# nrf9220_cellrf register map
Vendor: Nordic Semiconductor; Series: nRF92; File version: 1
CPU: CM0 r0p0, little endian, no MPU, no FPU, 2 interrupt priority bits, 33 interrupts
Registers are 32-bit, read-write, reset 0x0 unless marked. A register's access mark holds for its fields unless they carry their own. Offsets are from the block's base; [hi:lo] are bit positions; {n}, {i} and the like mark numbered series; 'fields as' and 'values as' point back to an identical list.

## GLOBAL_CTI210 — Cross-Trigger Interface control. NOTE: this is not a separate peripheral, but describes CM33 functionality. 0
Base 0xBF046000
Same registers: GLOBAL_CTI211 0xBF047000
0x00 CTICONTROL
  [0] GLBEN — Enables or disables the CTI.
    0=Disabled (All cross-triggering mapping logic functionality is disabled.); 1=Enabled (Cross-triggering mapping logic functionality is enabled.)
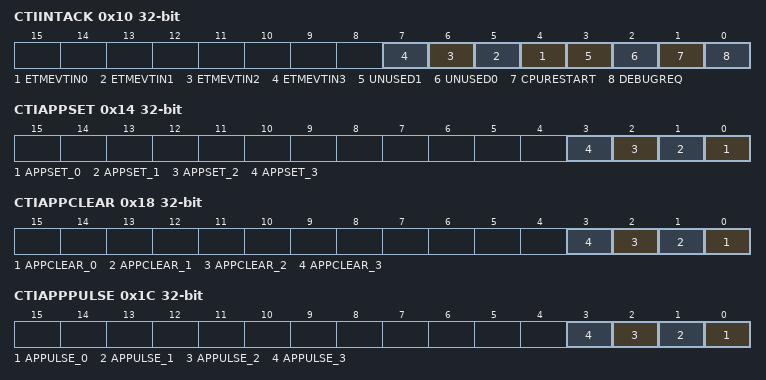
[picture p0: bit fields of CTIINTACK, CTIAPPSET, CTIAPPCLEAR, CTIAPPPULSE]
0x10 CTIINTACK wo — CTI Interrupt Acknowledge register
  [all] fields
    on write: 1=Acknowledge (Clears the ctitrigout.)
  [n+4] ETMEVTIN{n} (n=0..3) — ETM Event Input {n}
  [3] UNUSED1
  [2] UNUSED0
  [1] CPURESTART — Processor Restart
  [0] DEBUGREQ — Processor debug request
0x14 CTIAPPSET — CTI Application Trigger Set register
  [n] APPSET_{n} (n=0..3) — Application trigger event for channel {n}.
    on read: 0=Inactive (Application trigger {n} is inactive.); 1=Active (Application trigger {n} is active.) | on write: 1=Activate (Generate channel event for channel {n}.)
0x18 CTIAPPCLEAR wo — CTI Application Trigger Clear register
  [n] APPCLEAR_{n} (n=0..3) — Sets the corresponding bits in the CTIAPPSET to 0. There is one bit of the register for each channel.
    on write: 1=Clears the event for channel {n}
0x1C CTIAPPPULSE wo — CTI Application Pulse register
  [n] APPULSE_{n} (n=0..3) — Setting a bit HIGH generates a channel event pulse for the selected channel. There is one bit of the register for each channel.
    on write: 1=Generates an event pulse on channel {n}
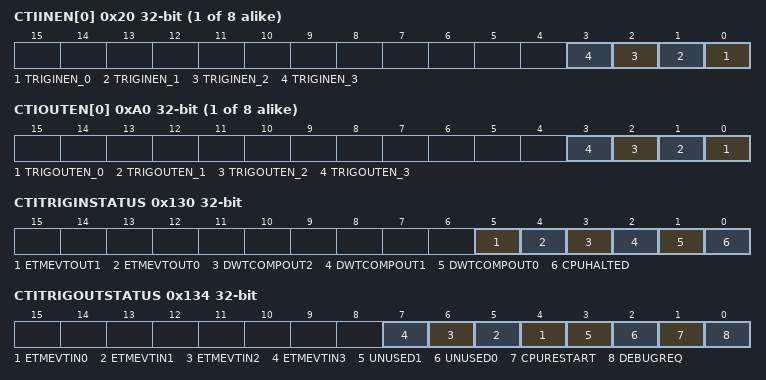
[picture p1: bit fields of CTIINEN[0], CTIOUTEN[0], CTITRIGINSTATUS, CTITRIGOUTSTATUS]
{0x20+4i} CTIINEN[{i}] (i=0..7) — Description collection: CTI Trigger input
  [n] TRIGINEN_{n} (n=0..3) — Enables a cross trigger event to channel {n} when a ctitrigin input is activated.
    0=Disabled (Input trigger n events are ignored by channel {n}.); 1=Enabled (When an event is received on input trigger n (ctitrigin[n]), generate an event on channel {n}.)
{0xA0+4i} CTIOUTEN[{i}] (i=0..7) — Description collection: CTI Trigger output
  [n] TRIGOUTEN_{n} (n=0..3) — Enables a cross trigger event to ctitrigout when channel {n} is activated.
    0=Disabled (Channel {n} is ignored by output trigger n.); 1=Enabled (When an event occurs on channel {n}, generate an event on output event n (ctitrigout[n]).)
0x130 CTITRIGINSTATUS ro — CTI Trigger In Status register Because the register provides a view of the raw ctitrigin inputs, the reset value is UNKNOWN.
  [all] fields
    1=Active (Ctitrigin is active.); 0=Inactive (Ctitrigin is inactive.)
  [5] ETMEVTOUT1 — ETM Event Output 1
  [4] ETMEVTOUT0 — ETM Event Output 0
  [3] DWTCOMPOUT2 — DWT Comparator Output 2
  [2] DWTCOMPOUT1 — DWT Comparator Output 1
  [1] DWTCOMPOUT0 — DWT Comparator Output 0
  [0] CPUHALTED — Processor Halted
0x134 CTITRIGOUTSTATUS ro — CTI Trigger Out Status register
  [all] fields
    1=Active (Ctitrigout is active.); 0=Inactive (Ctitrigout is inactive.)
  [n+4] ETMEVTIN{n} (n=0..3) — ETM Event Input {n}
  [3] UNUSED1
  [2] UNUSED0
  [1] CPURESTART — Processor Restart
  [0] DEBUGREQ — Processor debug request
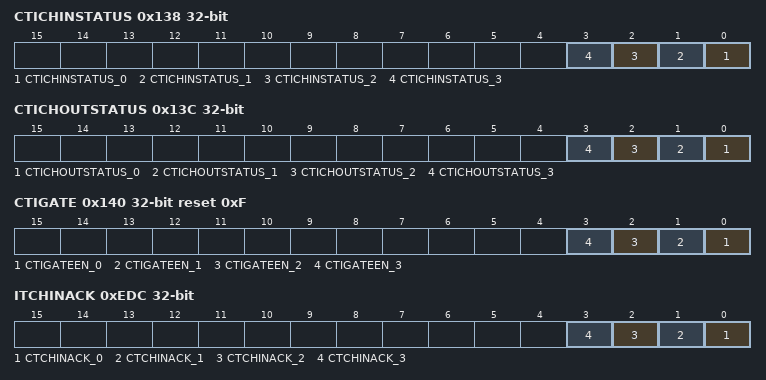
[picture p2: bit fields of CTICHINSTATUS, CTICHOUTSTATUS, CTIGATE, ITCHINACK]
0x138 CTICHINSTATUS ro — CTI Channel In Status register Because the register provides a view of the raw ctichin inputs, the reset value is UNKNOWN.
  [n] CTICHINSTATUS_{n} (n=0..3) — Shows the status of the ctitrigin {n} input.
    1=Active (Ctichin {n} is active.); 0=Inactive (Ctichin {n} is inactive.)
0x13C CTICHOUTSTATUS ro — CTI Channel Out Status register
  [n] CTICHOUTSTATUS_{n} (n=0..3) — Shows the status of the ctichout {n} output.
    1=Active (Ctichout {n} is active.); 0=Inactive (Ctichout {n} is inactive.)
0x140 CTIGATE reset 0xF — Enable CTI Channel Gate register
  [n] CTIGATEEN_{n} (n=0..3) — Enable ctichout{n}.
    1=Enabled (Enable ctichout channel {n} propagation.); 0=Disabled (Disable ctichout channel {n} propagation.)
0x144 ASICCTL — External Multiplexer Control register
  [7:0] ASICCTL — When external multiplexing is implemented for trigger signals, then the number of multiplexed signals on each trigger must be shown in the Device ID Register. This is done using a Verilog define EXTMUXNUM.
0xEDC ITCHINACK wo — Integration Test Channel Input Acknowledge register
  [n] CTCHINACK_{n} (n=0..3) — Sets the value of the ctichinack {n} output
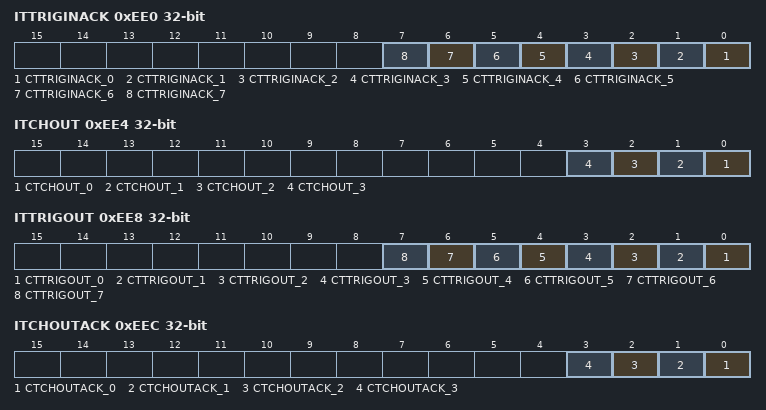
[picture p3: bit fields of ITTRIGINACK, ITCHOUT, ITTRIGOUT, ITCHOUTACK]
0xEE0 ITTRIGINACK wo — Integration Test Trigger Input Acknowledge register
  [n] CTTRIGINACK_{n} (n=0..7) — Sets the value of the ctitriginack {n} output
0xEE4 ITCHOUT wo — Integration Test Channel Output register
  [n] CTCHOUT_{n} (n=0..3) — Sets the value of the ctichout {n} output
0xEE8 ITTRIGOUT wo — Integration Test Trigger Output register
  [n] CTTRIGOUT_{n} (n=0..7) — Sets the value of the ctitrigout {n} output
0xEEC ITCHOUTACK ro — Integration Test Channel Output Acknowledge register
  [n] CTCHOUTACK_{n} (n=0..3) — Reads the value of the ctichoutack {n} input
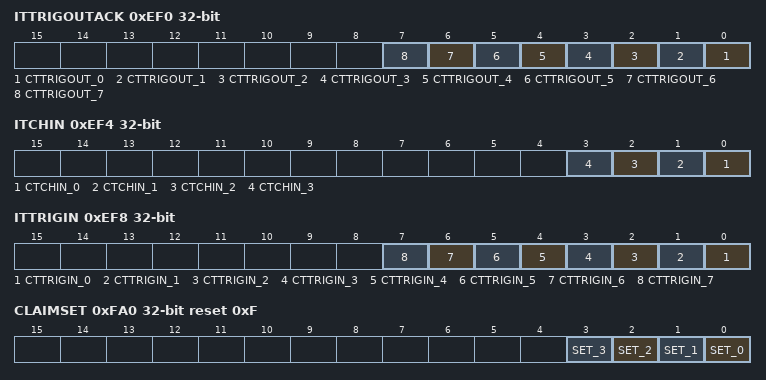
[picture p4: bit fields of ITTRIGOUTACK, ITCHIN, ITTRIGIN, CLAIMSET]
0xEF0 ITTRIGOUTACK ro — Integration Test Trigger Output Acknowledge register
  [n] CTTRIGOUT_{n} (n=0..7) — Reads the value of the ctitrigoutack {n} input
0xEF4 ITCHIN ro — Integration Test Channel Input register
  [n] CTCHIN_{n} (n=0..3) — Reads the value of the ctichin {n} input
0xEF8 ITTRIGIN ro — Integration Test Trigger input register
  [n] CTTRIGIN_{n} (n=0..7) — Reads the value of the ctitrigin {n} input
0xF00 ITCTRL — Integration Mode Control register
  [0] IME — Integration Mode Enable
    1=Enable integration mode; 0=Disable integration mode
0xFA0 CLAIMSET reset 0xF — Claim Tag Set register
  [n] SET_{n} (n=0..3) — Determines whether claim bit {n} is implemented
    on read: 1=Implemented (Claim tag bit {n} is implemented) | on write: 1=Claim (Set claim bit {n})
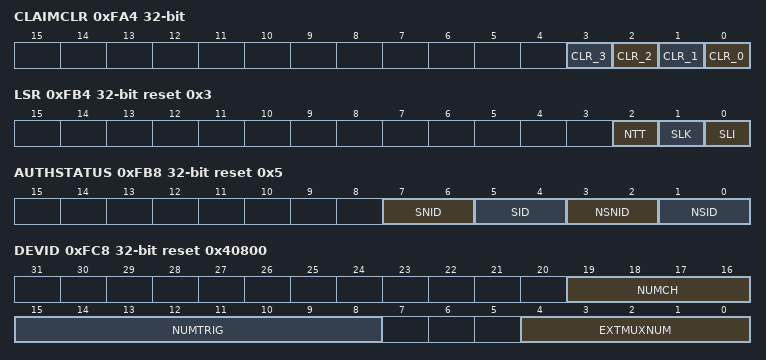
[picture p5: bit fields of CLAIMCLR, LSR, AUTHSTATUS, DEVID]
0xFA4 CLAIMCLR — Claim Tag Clear register
  [n] CLR_{n} (n=0..3) — Determines whether claim bit {n} is implemented
    on read: 0=Unclaimed (Claim tag bit {n} is not set); 1=Claimed (Claim tag bit {n} is set) | on write: 1=Unclaim (Clear bit {n} of the claim tag)
0xFB0 LAR wo — Lock Address Register
  [31:0] KEY — Software lock key value
    0xC5ACCE55=Clear the software lock
0xFB4 LSR ro reset 0x3 — Lock Status Register
  [2] NTT — Register size indicator. Always 0. Indicates that the LAR is implemented as 32-bit.
  [1] SLK — Software Lock Status. Returns the present lock status of the device, from the current interface
    0=Unlocked (Indicates that write operations are permitted from this interface); 1=Locked (Indicates that write operations are not permitted from this interface. Read operations are permitted)
  [0] SLI — Software Lock Implemented. Indicates that a lock control mechanism is present from this interface
    0=Absent (Indicates that a lock control mechanism is not present from this interface. Write operations to the LAR are ignored); 1=Present (Indicates that a lock control mechanism present from this interface)
0xFB8 AUTHSTATUS ro reset 0x5 — Authentication Status Register
  [7:6] SNID — Always 0b00. The security level for Secure non-invasive debug is not implemented or is controlled elsewhere
  [5:4] SID — Always 0b00. Secure invasive debug is not implemented or is controlled elsewhere
  [3:2] NSNID — Indicates the security level for Non-secure non-invasive debug
    2=Disabled (Non-secure non-invasive debug disabled); 3=Enabled (Non-secure non-invasive debug enabled)
  [1:0] NSID — Indicates the security level for Non-secure invasive debug
    2=Disabled (Non-secure invasive debug disabled); 3=Enabled (Non-secure invasive debug enabled)
0xFBC DEVARCH ro reset 0x47701A14 — Device Architecture register
  [0] Architecture — Contains the CTI device architecture.
0xFC8 DEVID ro reset 0x40800 — Device Configuration register
  [19:16] NUMCH — Number of ECT channels available.
  [15:8] NUMTRIG — Number of ECT triggers available.
  [4:0] EXTMUXNUM — Indicates the number of multiplexers available on Trigger Inputs and Trigger Outputs that are using asicctl. The default value of 0b00000 indicates that no multiplexing is present. This value of this bit depends on the Verilog define EXTMUXNUM that you must change accordingly.
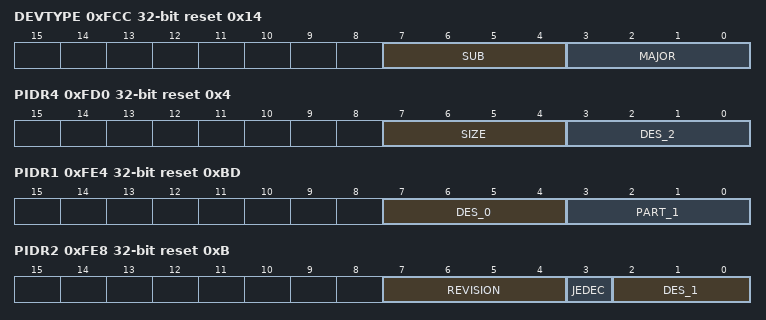
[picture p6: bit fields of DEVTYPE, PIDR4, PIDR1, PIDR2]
0xFCC DEVTYPE ro reset 0x14 — Device Type Identifier register
  [7:4] SUB — Sub-classification of the type of the debug component as specified in the Arm Architecture Specification within the major classification as specified in the MAJOR field.
    1=Crosstrigger (Indicates that this component is a sub-triggering component.)
  [3:0] MAJOR — Major classification of the type of the debug component as specified in the Arm Architecture Specification for this debug and trace component.
    4=Controller (Indicates that this component allows a debugger to control other components in an Arm CoreSight SoC-400 system.)
0xFD0 PIDR4 ro reset 0x4 — Peripheral ID4 Register
  [7:4] SIZE — Always 0b0000. Indicates that the device only occupies 4KB of memory.
  [3:0] DES_2 — Together, PIDR1.DES_0, PIDR2.DES_1, and PIDR4.DES_2 identify the designer of the component.
    4=Code (JEDEC continuation code.)
{0xFC0+4i} PIDR{i} ro (i=5..7) — Peripheral ID{i} register
0xFE0 PIDR0 ro reset 0x21 — Peripheral ID0 Register
  [7:0] PART_0 — Bits[7:0] of the 12-bit part number of the component. The designer of the component assigns this part number.
    33=PartnumberL (Indicates bits[7:0] of the part number of the component.)
0xFE4 PIDR1 ro reset 0xBD — Peripheral ID1 Register
  [7:4] DES_0 — Together, PIDR1.DES_0, PIDR2.DES_1, and PIDR4.DES_2 identify the designer of the component.
    11=Arm (Arm. Bits[3:0] of the JEDEC JEP106 Identity Code)
  [3:0] PART_1 — Bits[11:8] of the 12-bit part number of the component. The designer of the component assigns this part number.
    13=PartnumberH (Indicates bits[11:8] of the part number of the component.)
0xFE8 PIDR2 ro reset 0xB — Peripheral ID2 Register
  [7:4] REVISION — Peripheral revision
    0=Rev0p0 (This device is at r0p0)
  [3] JEDEC — Always 1. Indicates that the JEDEC-assigned designer ID is used.
  [2:0] DES_1 — Together, PIDR1.DES_0, PIDR2.DES_1, and PIDR4.DES_2 identify the designer of the component.
    3=Arm (Arm. Bits[6:4] of the JEDEC JEP106 Identity Code)
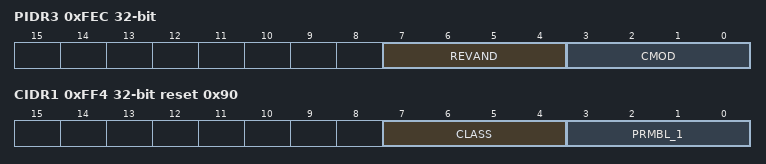
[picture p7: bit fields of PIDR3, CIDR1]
0xFEC PIDR3 ro — Peripheral ID3 Register
  [7:4] REVAND — Indicates minor errata fixes specific to the revision of the component being used, for example metal fixes after implementation. In most cases, this field is 0b0000. Arm recommends that the component designers ensure that a metal fix can change this field if required, for example, by driving it from registers that reset to 0b0000.
    0=NoErrata (Indicates that there are no errata fixes to this component.)
  [3:0] CMOD — Customer Modified. Indicates whether the customer has modified the behavior of the component. In most cases, this field is 0b0000. Customers change this value when they make authorized modifications to this component.
    0=Unmodified (Indicates that the customer has not modified this component.)
0xFF0 CIDR0 ro reset 0xD — Component ID0 Register
  [7:0] PRMBL_0 — Preamble[0]. Contains bits[7:0] of the component identification code.
    13=Value (Bits[7:0] of the identification code.)
0xFF4 CIDR1 ro reset 0x90 — Component ID1 Register
  [7:4] CLASS — Class of the component, for example, whether the component is a ROM table or a generic CoreSight component. Contains bits[15:12] of the component identification code
    9=Coresight (Indicates that the component is a CoreSight component.)
  [3:0] PRMBL_1 — Preamble[1]. Contains bits[11:8] of the component identification code.
    0=Value (Bits[11:8] of the identification code.)
0xFF8 CIDR2 ro reset 0x5 — Component ID2 Register
  [7:0] PRMBL_2 — Preamble[2]. Contains bits[23:16] of the component identification code.
    5=Value (Bits[23:16] of the identification code.)
0xFFC CIDR3 ro reset 0xB1 — Component ID3 Register
  [7:0] PRMBL_3 — Preamble[3]. Contains bits[31:24] of the component identification code.
    177=Value (Bits[31:24] of the identification code.)

## CTI — Cross-Trigger Interface control. NOTE: this is not a separate peripheral, but describes CM33 functionality.
Base 0xF0001000
Registers as GLOBAL_CTI210, without CTICONTROL, CTIINTACK, CTIAPPSET, CTIAPPCLEAR, CTIAPPPULSE, CTIINEN[*], CTIOUTEN[*], CTITRIGINSTATUS, CTITRIGOUTSTATUS, CTICHINSTATUS, CTICHOUTSTATUS, CTIGATE; these are added or differ:
0x00 CTICONTROL
  [0] GLBEN — Enables or disables the CTI.
    0=Disabled (All cross-triggering mapping logic functionality is disabled.); 1=Enabled (Cross-triggering mapping logic functionality is enabled.)
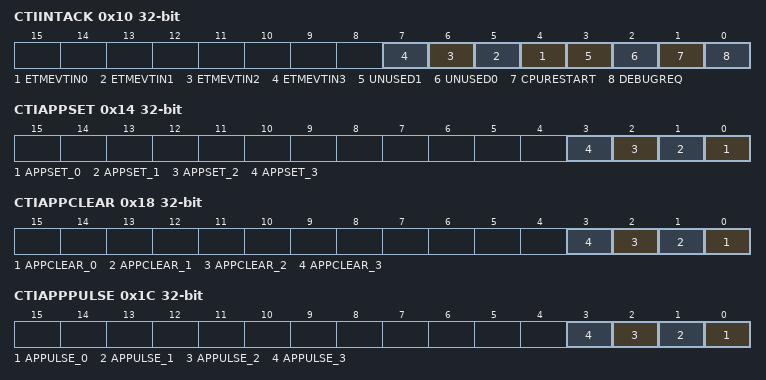
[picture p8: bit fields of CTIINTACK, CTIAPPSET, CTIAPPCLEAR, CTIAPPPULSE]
0x10 CTIINTACK wo — CTI Interrupt Acknowledge register
  fields as GLOBAL_CTI210.CTIINTACK
0x14 CTIAPPSET — CTI Application Trigger Set register
  fields as GLOBAL_CTI210.CTIAPPSET
0x18 CTIAPPCLEAR wo — CTI Application Trigger Clear register
  [n] APPCLEAR_{n} (n=0..3) — Sets the corresponding bits in the CTIAPPSET to 0. There is one bit of the register for each channel.
    on write: 1=Clears the event for channel {n}
0x1C CTIAPPPULSE wo — CTI Application Pulse register
  fields as GLOBAL_CTI210.CTIAPPPULSE
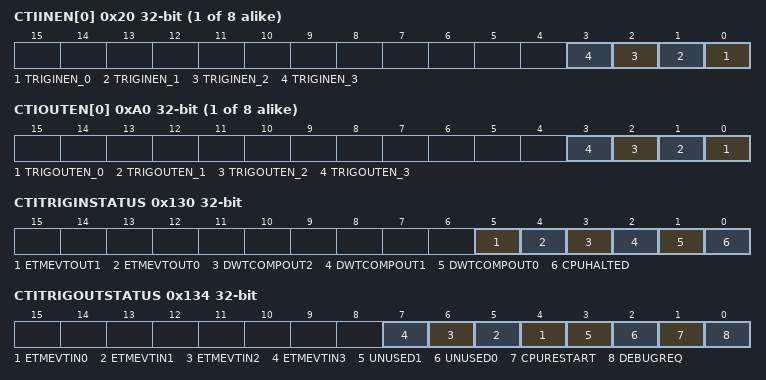
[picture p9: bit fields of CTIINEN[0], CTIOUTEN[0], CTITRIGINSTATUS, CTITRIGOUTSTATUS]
{0x20+4i} CTIINEN[{i}] (i=0..7) — Description collection: CTI Trigger input
  fields as GLOBAL_CTI210.CTIINEN[0]
{0xA0+4i} CTIOUTEN[{i}] (i=0..7) — Description collection: CTI Trigger output
  fields as GLOBAL_CTI210.CTIOUTEN[0]
0x130 CTITRIGINSTATUS ro — CTI Trigger In Status register Because the register provides a view of the raw ctitrigin inputs, the reset value is UNKNOWN.
  fields as GLOBAL_CTI210.CTITRIGINSTATUS
0x134 CTITRIGOUTSTATUS ro — CTI Trigger Out Status register
  fields as GLOBAL_CTI210.CTITRIGOUTSTATUS
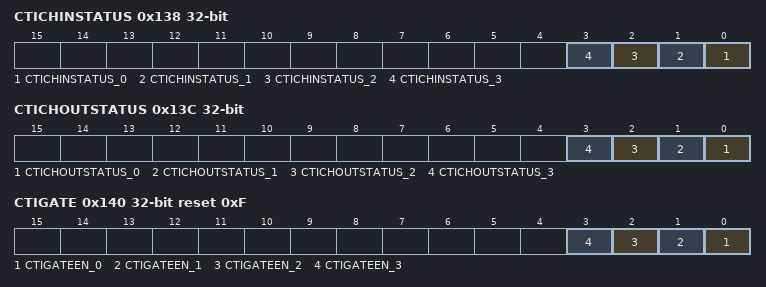
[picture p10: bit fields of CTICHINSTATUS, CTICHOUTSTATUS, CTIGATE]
0x138 CTICHINSTATUS ro — CTI Channel In Status register Because the register provides a view of the raw ctichin inputs, the reset value is UNKNOWN.
  [n] CTICHINSTATUS_{n} (n=0..3) — Shows the status of the ctitrigin {n} input.
    1=Active (Ctichin {n} is active.); 0=Inactive (Ctichin {n} is inactive.)
0x13C CTICHOUTSTATUS ro — CTI Channel Out Status register
  [n] CTICHOUTSTATUS_{n} (n=0..3) — Shows the status of the ctichout {n} output.
    1=Active (Ctichout {n} is active.); 0=Inactive (Ctichout {n} is inactive.)
0x140 CTIGATE reset 0xF — Enable CTI Channel Gate register
  [n] CTIGATEEN_{n} (n=0..3) — Enable ctichout{n}.
    1=Enabled (Enable ctichout channel {n} propagation.); 0=Disabled (Disable ctichout channel {n} propagation.)
0xFBC DEVARCH ro reset 0x47701A14 — Device Architecture register
  [0] Architecture — Contains the CTI device architecture.
